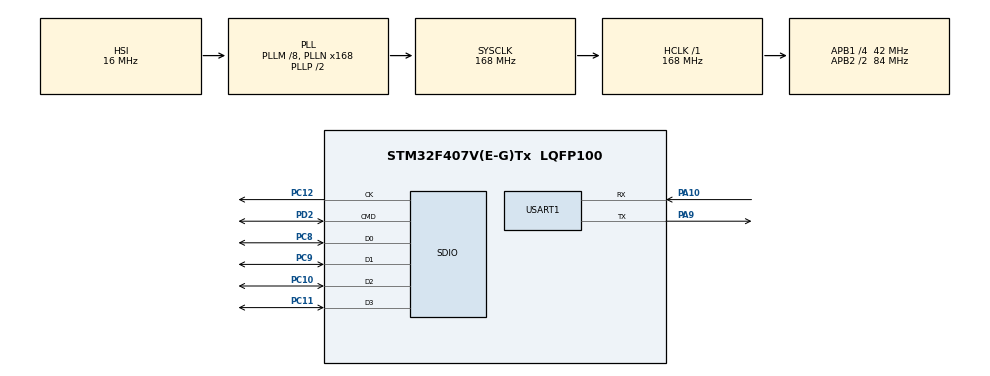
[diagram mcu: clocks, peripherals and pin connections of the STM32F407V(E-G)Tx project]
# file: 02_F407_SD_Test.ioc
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Dma.Request0=SDIO_TX
Dma.Request1=SDIO_RX
Dma.SDIO_RX.1.Direction=DMA_PERIPH_TO_MEMORY
Dma.SDIO_RX.1.FIFOMode=DMA_FIFOMODE_ENABLE
Dma.SDIO_RX.1.FIFOThreshold=DMA_FIFO_THRESHOLD_FULL
Dma.SDIO_RX.1.Instance=DMA2_Stream6
Dma.SDIO_RX.1.MemBurst=DMA_MBURST_INC4
Dma.SDIO_RX.1.MemDataAlignment=DMA_MDATAALIGN_WORD
Dma.SDIO_RX.1.MemInc=DMA_MINC_ENABLE
Dma.SDIO_RX.1.Mode=DMA_PFCTRL
Dma.SDIO_RX.1.PeriphBurst=DMA_PBURST_INC4
Dma.SDIO_RX.1.PeriphDataAlignment=DMA_PDATAALIGN_WORD
Dma.SDIO_RX.1.PeriphInc=DMA_PINC_DISABLE
Dma.SDIO_RX.1.Priority=DMA_PRIORITY_LOW
Dma.SDIO_TX.0.Direction=DMA_MEMORY_TO_PERIPH
Dma.SDIO_TX.0.FIFOMode=DMA_FIFOMODE_ENABLE
Dma.SDIO_TX.0.FIFOThreshold=DMA_FIFO_THRESHOLD_FULL
Dma.SDIO_TX.0.Instance=DMA2_Stream3
Dma.SDIO_TX.0.MemBurst=DMA_MBURST_INC4
Dma.SDIO_TX.0.MemDataAlignment=DMA_MDATAALIGN_WORD
Dma.SDIO_TX.0.MemInc=DMA_MINC_ENABLE
Dma.SDIO_TX.0.Mode=DMA_PFCTRL
Dma.SDIO_TX.0.PeriphBurst=DMA_PBURST_INC4
Dma.SDIO_TX.0.PeriphDataAlignment=DMA_PDATAALIGN_WORD
Dma.SDIO_TX.0.PeriphInc=DMA_PINC_DISABLE
Dma.SDIO_TX.0.Priority=DMA_PRIORITY_LOW
Mcu.Family=STM32F4
Mcu.Name=STM32F407V(E-G)Tx
Mcu.Package=LQFP100
NVIC.DMA2_Stream3_IRQn=true\:0\:0\:false\:false\:true\:false\:true\:true
NVIC.DMA2_Stream6_IRQn=true\:0\:0\:false\:false\:true\:false\:true\:true
NVIC.PriorityGroup=NVIC_PRIORITYGROUP_4
NVIC.SDIO_IRQn=true\:0\:0\:false\:false\:true\:true\:true\:true
PA10.Mode=Asynchronous
PA10.Signal=USART1_RX
PA13.Mode=Serial_Wire
PA13.Signal=SYS_JTMS-SWDIO
PA14.Mode=Serial_Wire
PA14.Signal=SYS_JTCK-SWCLK
PA9.Mode=Asynchronous
PA9.Signal=USART1_TX
PC10.Mode=SD_4_bits_Wide_bus
PC10.Signal=SDIO_D2
PC11.Mode=SD_4_bits_Wide_bus
PC11.Signal=SDIO_D3
PC12.Mode=SD_4_bits_Wide_bus
PC12.Signal=SDIO_CK
PC8.Mode=SD_4_bits_Wide_bus
PC8.Signal=SDIO_D0
PC9.Mode=SD_4_bits_Wide_bus
PC9.Signal=SDIO_D1
PD2.Mode=SD_4_bits_Wide_bus
PD2.Signal=SDIO_CMD
PH0-OSC_IN.Mode=HSE-External-Oscillator
PH0-OSC_IN.Signal=RCC_OSC_IN
PH1-OSC_OUT.Mode=HSE-External-Oscillator
PH1-OSC_OUT.Signal=RCC_OSC_OUT
ProjectManager.HeapSize=0x200
ProjectManager.StackSize=0x400
ProjectManager.TargetToolchain=MDK-ARM V5.32
RCC.48MHZClocksFreq_Value=48000000
RCC.AHBFreq_Value=168000000
RCC.APB1CLKDivider=RCC_HCLK_DIV4
RCC.APB1Freq_Value=42000000
RCC.APB1TimFreq_Value=84000000
RCC.APB2CLKDivider=RCC_HCLK_DIV2
RCC.APB2Freq_Value=84000000
RCC.APB2TimFreq_Value=168000000
RCC.CortexFreq_Value=168000000
RCC.HCLKFreq_Value=168000000
RCC.HSE_VALUE=25000000
RCC.HSI_VALUE=16000000
RCC.LSE_VALUE=32768
RCC.PLLM=8
RCC.PLLN=168
RCC.PLLQ=7
RCC.SYSCLKFreq_VALUE=168000000
RCC.SYSCLKSource=RCC_SYSCLKSOURCE_PLLCLK
RCC.VCOOutputFreq_Value=336000000
USART1.VirtualMode=VM_ASYNC
board=custom

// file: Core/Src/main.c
/* USER CODE BEGIN Header */
/**
  ******************************************************************************
  * @file           : main.c
  * @brief          : Main program body
  ******************************************************************************
  * @attention
  *
  * Copyright (c) 2025 STMicroelectronics.
  * All rights reserved.
  *
  * This software is licensed under terms that can be found in the LICENSE file
  * in the root directory of this software component.
  * If no LICENSE file comes with this software, it is provided AS-IS.
  *
  ******************************************************************************
  */
/* USER CODE END Header */
#include "main.h"

/* USER CODE BEGIN Includes */
#include "sd_card.h"
/* USER CODE END Includes */

/* USER CODE BEGIN PD */

	 /* __GNUC__*/
/* USER CODE END PD */

SD_HandleTypeDef hsd;
DMA_HandleTypeDef hdma_sdio_tx;
DMA_HandleTypeDef hdma_sdio_rx;

UART_HandleTypeDef huart1;

void SystemClock_Config(void);
static void MX_GPIO_Init(void);
static void MX_DMA_Init(void);
static void MX_SDIO_SD_Init(void);
static void MX_USART1_UART_Init(void);

/* USER CODE BEGIN 0 */

 /******************************************************************
     *@brief  Retargets the C library printf  function to the USART.
     *@param  None
     *@retval None
 ******************************************************************/
 PUTCHAR_PROTOTYPE
 {
     HAL_UART_Transmit(&huart1, (uint8_t *)&ch,1,0xFFFF);
     return ch;
 }

/* USER CODE END 0 */

int main(void)
{

  /* MCU Configuration--------------------------------------------------------*/

  /* Reset of all peripherals, Initializes the Flash interface and the Systick. */
  HAL_Init();

  /* Configure the system clock */
  SystemClock_Config();

  /* Initialize all configured peripherals */
  MX_GPIO_Init();
  MX_DMA_Init();
  MX_SDIO_SD_Init();
  MX_USART1_UART_Init();
  /* USER CODE BEGIN 2 */

//    setvbuf(stdout, NULL, _IONBF, 0);
    printf("初始化完毕\n\r");

    SDCard_ShowInfo();
    SDCard_EraseBlocks();
    SDCard_TestWrite();
    SDCard_TestRead();

  /* USER CODE END 2 */

  /* Infinite loop */
  while (1)
  {

  }
}

void SystemClock_Config(void)
{
  RCC_OscInitTypeDef RCC_OscInitStruct = {0};
  RCC_ClkInitTypeDef RCC_ClkInitStruct = {0};

  /** Configure the main internal regulator output voltage
  */
  __HAL_RCC_PWR_CLK_ENABLE();
  __HAL_PWR_VOLTAGESCALING_CONFIG(PWR_REGULATOR_VOLTAGE_SCALE1);

  /** Initializes the RCC Oscillators according to the specified parameters
  * in the RCC_OscInitTypeDef structure.
  */
  RCC_OscInitStruct.OscillatorType = RCC_OSCILLATORTYPE_HSI;
  RCC_OscInitStruct.HSIState = RCC_HSI_ON;
  RCC_OscInitStruct.HSICalibrationValue = RCC_HSICALIBRATION_DEFAULT;
  RCC_OscInitStruct.PLL.PLLState = RCC_PLL_ON;
  RCC_OscInitStruct.PLL.PLLSource = RCC_PLLSOURCE_HSI;
  RCC_OscInitStruct.PLL.PLLM = 8;
  RCC_OscInitStruct.PLL.PLLN = 168;
  RCC_OscInitStruct.PLL.PLLP = RCC_PLLP_DIV2;
  RCC_OscInitStruct.PLL.PLLQ = 7;
  if (HAL_RCC_OscConfig(&RCC_OscInitStruct) != HAL_OK)
  {
    Error_Handler();
  }

  /** Initializes the CPU, AHB and APB buses clocks
  */
  RCC_ClkInitStruct.ClockType = RCC_CLOCKTYPE_HCLK|RCC_CLOCKTYPE_SYSCLK
                              |RCC_CLOCKTYPE_PCLK1|RCC_CLOCKTYPE_PCLK2;
  RCC_ClkInitStruct.SYSCLKSource = RCC_SYSCLKSOURCE_PLLCLK;
  RCC_ClkInitStruct.AHBCLKDivider = RCC_SYSCLK_DIV1;
  RCC_ClkInitStruct.APB1CLKDivider = RCC_HCLK_DIV4;
  RCC_ClkInitStruct.APB2CLKDivider = RCC_HCLK_DIV2;

  if (HAL_RCC_ClockConfig(&RCC_ClkInitStruct, FLASH_LATENCY_5) != HAL_OK)
  {
    Error_Handler();
  }
}

static void MX_SDIO_SD_Init(void)
{

  hsd.Instance = SDIO;
  hsd.Init.ClockEdge = SDIO_CLOCK_EDGE_RISING;
  hsd.Init.ClockBypass = SDIO_CLOCK_BYPASS_DISABLE;
  hsd.Init.ClockPowerSave = SDIO_CLOCK_POWER_SAVE_DISABLE;
  hsd.Init.BusWide = SDIO_BUS_WIDE_1B;
  hsd.Init.HardwareFlowControl = SDIO_HARDWARE_FLOW_CONTROL_DISABLE;
  hsd.Init.ClockDiv = 0;
  if (HAL_SD_Init(&hsd) != HAL_OK)
  {
    Error_Handler();
  }
  if (HAL_SD_ConfigWideBusOperation(&hsd, SDIO_BUS_WIDE_4B) != HAL_OK)
  {
    Error_Handler();
  }

}

static void MX_USART1_UART_Init(void)
{

  huart1.Instance = USART1;
  huart1.Init.BaudRate = 115200;
  huart1.Init.WordLength = UART_WORDLENGTH_8B;
  huart1.Init.StopBits = UART_STOPBITS_1;
  huart1.Init.Parity = UART_PARITY_NONE;
  huart1.Init.Mode = UART_MODE_TX_RX;
  huart1.Init.HwFlowCtl = UART_HWCONTROL_NONE;
  huart1.Init.OverSampling = UART_OVERSAMPLING_16;
  if (HAL_UART_Init(&huart1) != HAL_OK)
  {
    Error_Handler();
  }

}

static void MX_DMA_Init(void)
{

  /* DMA controller clock enable */
  __HAL_RCC_DMA2_CLK_ENABLE();

  /* DMA interrupt init */
  /* DMA2_Stream3_IRQn interrupt configuration */
  HAL_NVIC_SetPriority(DMA2_Stream3_IRQn, 0, 0);
  HAL_NVIC_EnableIRQ(DMA2_Stream3_IRQn);
  /* DMA2_Stream6_IRQn interrupt configuration */
  HAL_NVIC_SetPriority(DMA2_Stream6_IRQn, 0, 0);
  HAL_NVIC_EnableIRQ(DMA2_Stream6_IRQn);

}

static void MX_GPIO_Init(void)
{

  /* GPIO Ports Clock Enable */
  __HAL_RCC_GPIOH_CLK_ENABLE();
  __HAL_RCC_GPIOC_CLK_ENABLE();
  __HAL_RCC_GPIOA_CLK_ENABLE();
  __HAL_RCC_GPIOD_CLK_ENABLE();

}

void Error_Handler(void)
{
  __disable_irq();
  while (1)
  {
  }
}
